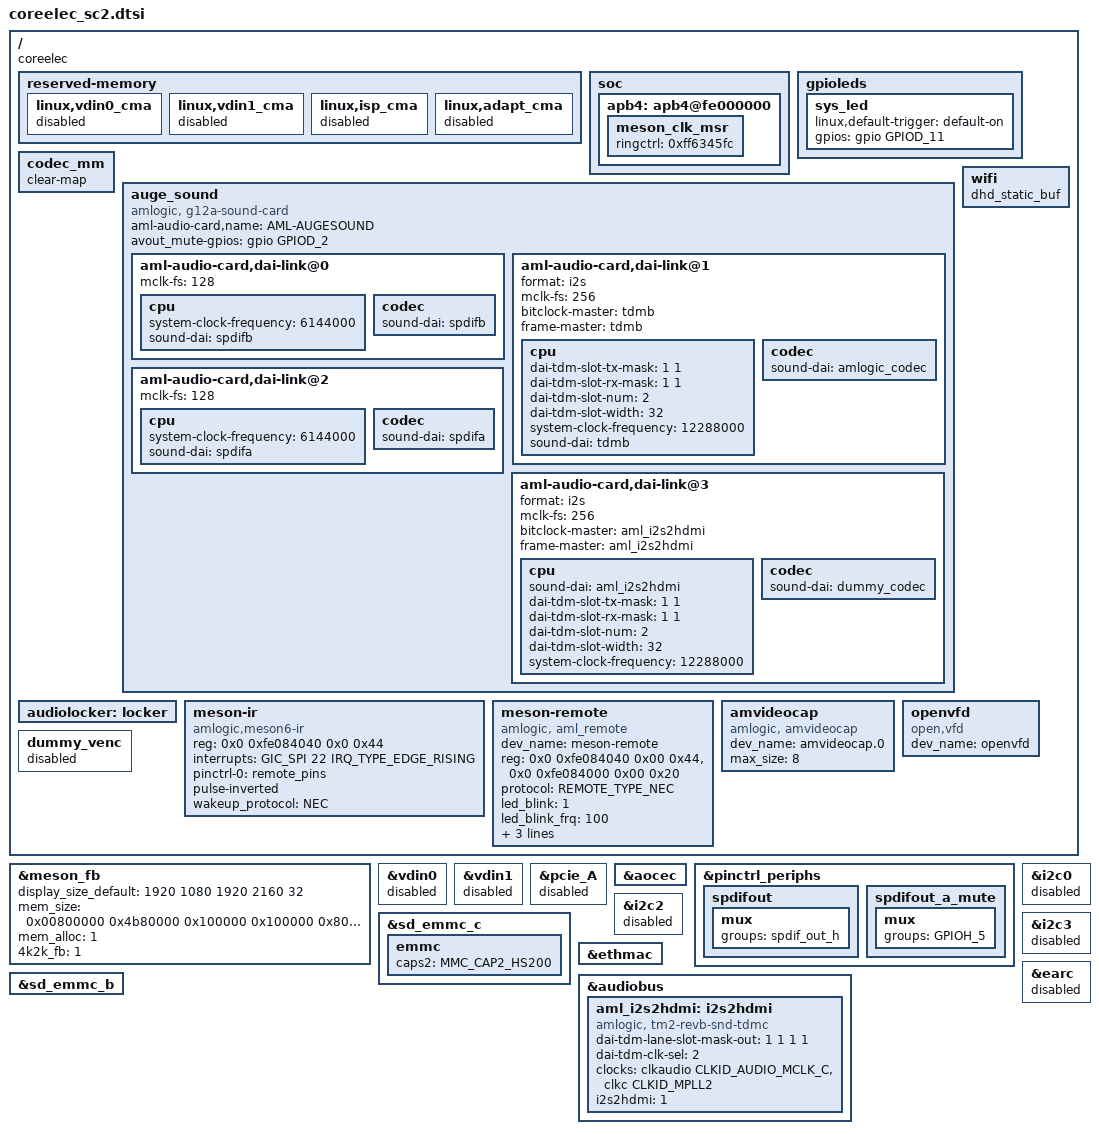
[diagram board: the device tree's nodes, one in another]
#include <dt-bindings/media/rc-map.h>
#include "sc2_s905x4_ah212.dts"

/ {
	coreelec;
	/delete-property/ amlogic-dt-id;

	reserved-memory {
		linux,vdin0_cma {
			status = "disabled";
		};
		linux,vdin1_cma {
			status = "disabled";
		};
		linux,isp_cma {
			status = "disabled";
		};
		linux,adapt_cma {
			status = "disabled";
		};
	};

	soc {
		apb4: apb4@fe000000 {
			meson_clk_msr {
				ringctrl = <0xff6345fc>;
			};
		};
	};

	gpioleds {
		status = "okay";
		/delete-node/ net_red;
		/delete-node/ net_green;
		/delete-node/ remote_led;
		sys_led {
			/delete-property/ retain-state-suspended;
			/delete-property/ default-state;
			linux,default-trigger="default-on";
			gpios = <&gpio GPIOD_11 GPIO_ACTIVE_HIGH>;
		};
	};

	codec_mm {
		clear-map;
	};

	/delete-node/ auge_sound;
	auge_sound {
		compatible = "amlogic, g12a-sound-card";
		aml-audio-card,name = "AML-AUGESOUND";

		/*avout mute gpio*/
		avout_mute-gpios = <&gpio GPIOD_2 GPIO_ACTIVE_HIGH>;

		aml-audio-card,dai-link@0 {
			mclk-fs = <128>;
			cpu {
				system-clock-frequency = <6144000>;
				sound-dai = <&spdifb>;
			};
			codec {
				sound-dai = <&spdifb>;
			};
		};

		aml-audio-card,dai-link@1 {
			format = "i2s";
			mclk-fs = <256>;
			bitclock-master = <&tdmb>;
			frame-master = <&tdmb>;
			cpu {
				dai-tdm-slot-tx-mask = <1 1>;
				dai-tdm-slot-rx-mask = <1 1>;
				dai-tdm-slot-num = <2>;
				dai-tdm-slot-width = <32>;
				system-clock-frequency = <12288000>;
				sound-dai = <&tdmb>;
			};
			codec {
				sound-dai = <&amlogic_codec>;
			};
		};

		aml-audio-card,dai-link@2 {
			mclk-fs = <128>;
			cpu {
				system-clock-frequency = <6144000>;
				sound-dai = <&spdifa>;
			};
			codec {
				sound-dai = <&spdifa>;
			};
		};

		aml-audio-card,dai-link@3 {
			format = "i2s";
			mclk-fs = <256>;
			bitclock-master = <&aml_i2s2hdmi>;
			frame-master = <&aml_i2s2hdmi>;
			cpu {
				sound-dai = <&aml_i2s2hdmi>;
				dai-tdm-slot-tx-mask = <1 1>;
				dai-tdm-slot-rx-mask = <1 1>;
				dai-tdm-slot-num = <2>;
				dai-tdm-slot-width = <32>;
				system-clock-frequency = <12288000>;
			};
			codec {
				sound-dai = <&dummy_codec>;
			};
		};
	};

	wifi{
		dhd_static_buf; /* if use bcm wifi, config dhd_static_buf */
	};

	audiolocker: locker {
		status = "okay";
	};

	/delete-node/ partitions;
	/delete-node/ firmware;

	/delete-node/ rc@0xfe084000;
	/delete-node/ custom_maps;

	meson-ir {
		compatible = "amlogic,meson6-ir";
		/* Multi-format IR controller */
		reg = <0x0 0xfe084040 0x0 0x44>;
		interrupts = <GIC_SPI 22 IRQ_TYPE_EDGE_RISING>;
		pinctrl-names = "default";
		pinctrl-0 = <&remote_pins>;
		pulse-inverted;
		wakeup_protocol = <NEC>; /* force default NEC by <dt-bindings/media/rc-map.h> */
		status = "okay";
	};
	meson-remote {
		compatible = "amlogic, aml_remote";
		dev_name = "meson-remote";
		reg = <0x0 0xfe084040 0x00 0x44>, /*Multi-format IR controller*/
			<0x0 0xfe084000 0x00 0x20>; /*Legacy IR controller*/
		status = "okay";
		protocol = <REMOTE_TYPE_NEC>;
		led_blink = <1>;
		led_blink_frq = <100>;
		interrupts = <GIC_SPI 22 IRQ_TYPE_EDGE_RISING>;
		pinctrl-names = "default";
		pinctrl-0 = <&remote_pins>;
		max_frame_time = <200>; /*set software decoder max frame time*/
	};

	amvideocap {
		compatible = "amlogic, amvideocap";
		dev_name = "amvideocap.0";
		status = "okay";
		max_size = <8>;//8M
	};

	openvfd {
		compatible = "open,vfd";
		dev_name = "openvfd";
		status = "okay";
	};

	dummy_venc: dummy_venc {
		status = "disabled";
	};

	/delete-node/ adc_keypad;
};

&meson_fb {
	display_size_default = <1920 1080 1920 2160 32>;
	mem_size = <0x00800000 0x4b80000 0x100000 0x100000 0x800000>;
	mem_alloc = <1>;
	4k2k_fb = <1>;
};

&vdin0 {
	status = "disabled";
};

&vdin1 {
	status = "disabled";
};

/delete-node/ &nand;

&pcie_A {
	status = "disabled";
};

&aocec {
	/delete-property/ arc_port_mask;
};

&pinctrl_periphs {
	spdifout: spdifout {
		mux { /* GPIOH_4 */
			groups = "spdif_out_h";
		};
	};

	spdifout_a_mute: spdifout_a_mute {
		mux { /* GPIOH_5 */
			groups = "GPIOH_5";
		};
	};
};

&sd_emmc_c {
	emmc {
		caps2 = "MMC_CAP2_HS200";
	};
};

&sd_emmc_b {
	status = "okay";
};

&i2c0 {
	status = "disabled";
	/delete-node/ gt9xx@5d;
	/delete-node/ ftxx@38;
};

&i2c2 {
	status = "disabled";
};

&i2c3 {
	status = "disabled";
	/delete-node/ ad82584f_62@62;
	/delete-node/ bl_extern_i2c;
	/delete-node/ tlc59116@60;
};

&ethmac {
	status = "okay";
};

&audiobus {
	aml_i2s2hdmi: i2s2hdmi {
		compatible = "amlogic, tm2-revb-snd-tdmc";
		#sound-dai-cells = <0>;
		dai-tdm-lane-slot-mask-out = <1 1 1 1>;
		dai-tdm-clk-sel = <2>;
		clocks = <&clkaudio CLKID_AUDIO_MCLK_C
				&clkc CLKID_MPLL2>;
		clock-names = "mclk", "clk_srcpll";
		i2s2hdmi = <1>;
		status = "okay";
	};

	/delete-node/ tdma;
	/delete-node/ tdm@0;
	/delete-node/ tdmc;
	/delete-node/ tdm@2;
	/delete-node/ tdm@3;
	/delete-node/ pdm;
};

&earc {
	status = "disabled";
};
